# WDTIMER3_DSP register map
Vendor: Texas Instruments
Peripheral module from a debugger description file (folder omap4430).
Registers are 32-bit, access per field, reset 0x0 unless marked. A register's access mark holds for its fields unless they carry their own. Offsets are as the file gives them; lines under a group give offsets from that group; [hi:lo] are bit positions; {n}, {i} and the like mark numbered series; 'fields as' and 'values as' point back to an identical list; <NAME> marks a mode.

## WDTIMER3_DSP
0x00 WDT_WIDR ro reset not defined — IP revision identifier
  [31:0] REVISION — IP Revision
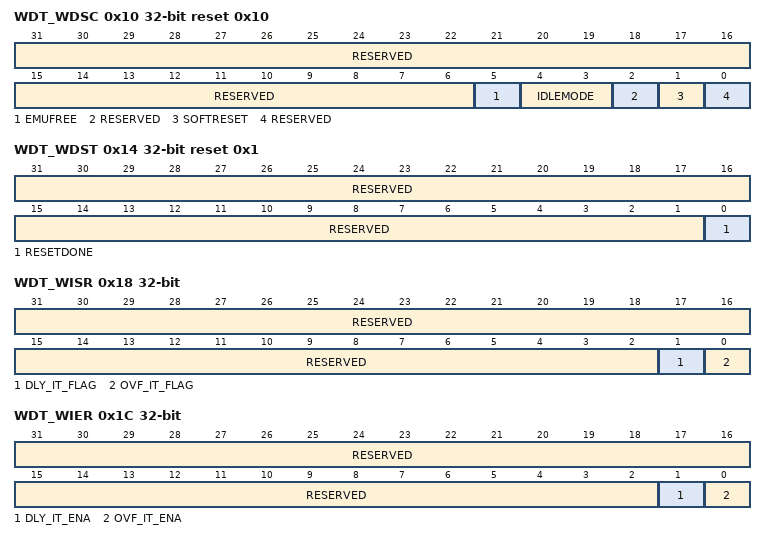
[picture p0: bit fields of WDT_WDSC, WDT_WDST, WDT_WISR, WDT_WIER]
0x10 WDT_WDSC reset 0x10 — This register controls the various parameters of the L4 interface.
  [31:6] RESERVED ro — Write os for future compatibility. Reads return 0.
  [5] EMUFREE rw — Emulation mode
    0=Timer counter frozen in emulation; 1=Timer counter free-running in emulation
  [4:3] IDLEMODE rw — Configuration of the local target state management mode. By definition, target can handle read/write transaction as long as it is out of IDLE state.
    0=Force-idle mode: local target IDLE state follows (acknowledges) the system idle requests unconditionally, that is, regardless of the IP module internal requirements. Backup mode, for debug only.; 1=No-idle mode: local target never enters IDLE state. Backup mode, for debug only.; 2=Smart-idle mode: local target IDLE state eventually follows (acknowledges) the system idle requests, depending on the IP module internal requirements. IP module should not generate (IRQ- or DMA-request-related) wake-up events.; 3=Smart-idle wake-up-capable mode: local target IDLE state eventually follows (acknowledges) the system idle requests, depending on the IP module internal requirements. IP module may generate (IRQ- or DMA-request-related) wake-up events when in IDLE state. Mode is relevant only if the appropriate IP moduleswake-up output(s) is (are) implemented.
  [2] RESERVED ro — Write 0s for future compatibility. Reads return 0.
  [1] SOFTRESET rw — Software reset. (Optional)
    0=SOFTRESET_0_r (Reset done, no pending action); 0=SOFTRESET_0_w (No action); 1=SOFTRESET_1_w (Initiate software reset.); 1=SOFTRESET_1_r (Reset (software or other) ongoing)
  [0] RESERVED ro — Write os for future compatibility. Reads return 0.
0x14 WDT_WDST ro reset 0x1 — This register provides status information about the module.
  [31:1] RESERVED — Reads return 0.
  [0] RESETDONE — Internal module reset monitoring
    0=RESETDONE_0_r (Internal module reset is ongoing.); 1=RESETDONE_1_r (Reset completed)
0x18 WDT_WISR access not given — This register shows which interrupt events are pending inside the module.
  [31:2] RESERVED ro — Reads return 0.
  [1] DLY_IT_FLAG — Pending delay interrupt status. (access RW W1toClr)
    0=DLY_IT_FLAG_0_r (No delay interrupt pending); 0=DLY_IT_FLAG_0_w (Status unchanged); 1=DLY_IT_FLAG_1_w (Status bit cleared); 1=DLY_IT_FLAG_1_r (Delay interrupt pending)
  [0] OVF_IT_FLAG — Pending overflow interrupt status. (access RW W1toClr)
    0=OVF_IT_FLAG_0_r (No overflow interrupt pending); 0=OVF_IT_FLAG_0_w (Status unchanged); 1=OVF_IT_FLAG_1_w (Status bit cleared); 1=OVF_IT_FLAG_1_r (Overflow interrupt pending)
0x1C WDT_WIER — This register controls (enable/disable) the interrupt events.
  [31:2] RESERVED ro — Reads return 0.
  [1] DLY_IT_ENA rw — Delay interrupt enable/disable
    0=Disable delay interrupt; 1=Enable delay interrupt
  [0] OVF_IT_ENA rw — Overflow interrupt enable/disable
    0=Disable overflow interrupt; 1=Enable overflow interrupt
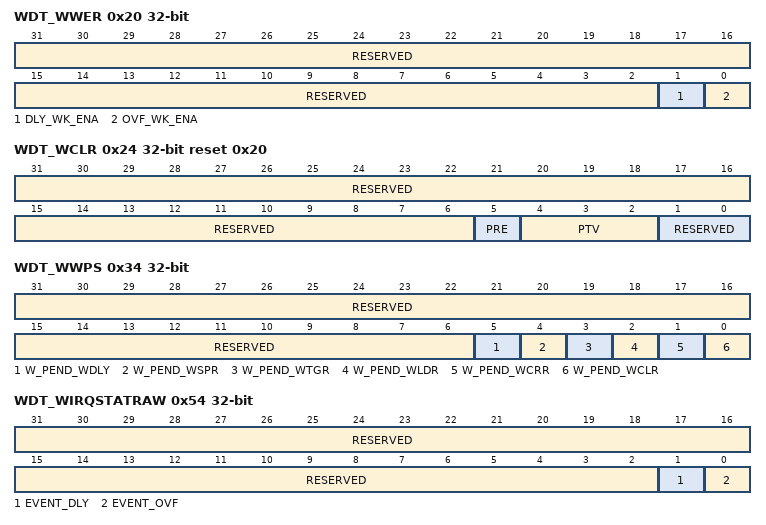
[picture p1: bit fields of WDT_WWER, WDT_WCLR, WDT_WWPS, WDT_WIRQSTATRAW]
0x20 WDT_WWER — This register controls (enable/disable) the wake-up events.
  [31:2] RESERVED ro — Write 0s for future compatibility. Reads return 0.
  [1] DLY_WK_ENA rw — Delay wake-up enable
    0=Disable delay wakeup; 1=Enable delay wakeup
  [0] OVF_WK_ENA rw — Overflow wake-up enable
    0=Disable overflow wakeup; 1=Enable overflow wakeup
0x24 WDT_WCLR reset 0x20 — This register controls the prescaler stage of the counter.
  [31:6] RESERVED ro — Reads return 0.
  [5] PRE rw — Prescaler enable/disable configuration
    0=Prescaler disabled; 1=Prescaler enabled
  [4:2] PTV rw — Prescaler value The timer counter is prescaled with the value: 2. Example: PTV = 3 -&gt; counter increases value if started after 8 functional clock periods. On reset, it is loaded from PI_PTV_RESET_VALUE input port.
  [1:0] RESERVED ro — Write 0s for future compatibility. Reads return 0.
0x28 WDT_WCRR rw — This register holds the value of the internal counter.
  [31:0] TIMER_COUNTER — Value of the timer counter register
0x2C WDT_WLDR rw — This register holds the timer load value.
  [31:0] TIMER_LOAD — Value of the timer load register
0x30 WDT_WTGR rw — Writing a different value than the one already written in this register does a watchdog counter reload.
  [31:0] TTGR_VALUE — Value of the trigger register
0x34 WDT_WWPS ro — This register contains the write posting bits for all writeable functional registers.
  [31:6] RESERVED — Write 0s for future compatibility. Reads return 0.
  [5] W_PEND_WDLY — Write pending for register WDLY
    0=W_PEND_WDLY_0_r (No register write pending); 1=W_PEND_WDLY_1_r (Register write pending)
  [4] W_PEND_WSPR — Write pending for register WSPR
    0=W_PEND_WSPR_0_r (No register write pending); 1=W_PEND_WSPR_1_r (Register write pending)
  [3] W_PEND_WTGR — Write pending for register WTGR
    0=W_PEND_WTGR_0_r (No register write pending); 1=W_PEND_WTGR_1_r (Register write pending)
  [2] W_PEND_WLDR — Write pending for register WLDR
    0=W_PEND_WLDR_0_r (No register write pending); 1=W_PEND_WLDR_1_r (Register write pending)
  [1] W_PEND_WCRR — Write pending for register WCRR
    0=W_PEND_WCRR_0_r (No register write pending); 1=W_PEND_WCRR_1_r (Register write pending)
  [0] W_PEND_WCLR — Write pending for register WCLR
    0=W_PEND_WCLR_0_r (No register write pending); 1=W_PEND_WCLR_1_r (Register write pending)
0x44 WDT_WDLY rw — This register holds the delay value that controls the internal pre-overflow event detection.
  [31:0] WDLY_VALUE — Value of the delay register
0x48 WDT_WSPR rw — This register holds the start-stop value that controls the internal start-stop FSM.
  [31:0] WSPR_VALUE — Value of the start-stop register
0x54 WDT_WIRQSTATRAW access not given — IRQ unmasked status, status set per-event raw interrupt status vector, line 0. Raw status is set even if event is not enabled. Write 1 to set the (raw) status, mostly for debug.
  [31:2] RESERVED ro — Write 0s for future compatibility. Reads return 0.
  [1] EVENT_DLY — Settable raw status for delay event (access RW W1toSet)
    0=EVENT_DLY_0_r (No event pending); 0=EVENT_DLY_0_w (No action); 1=EVENT_DLY_1_w (Set event (debug)); 1=EVENT_DLY_1_r (Event pending)
  [0] EVENT_OVF — Settable raw status for overflow event (access RW W1toSet)
    0=EVENT_OVF_0_r (No event pending); 0=EVENT_OVF_0_w (No action); 1=EVENT_OVF_1_w (Set event (debug)); 1=EVENT_OVF_1_r (Event pending)
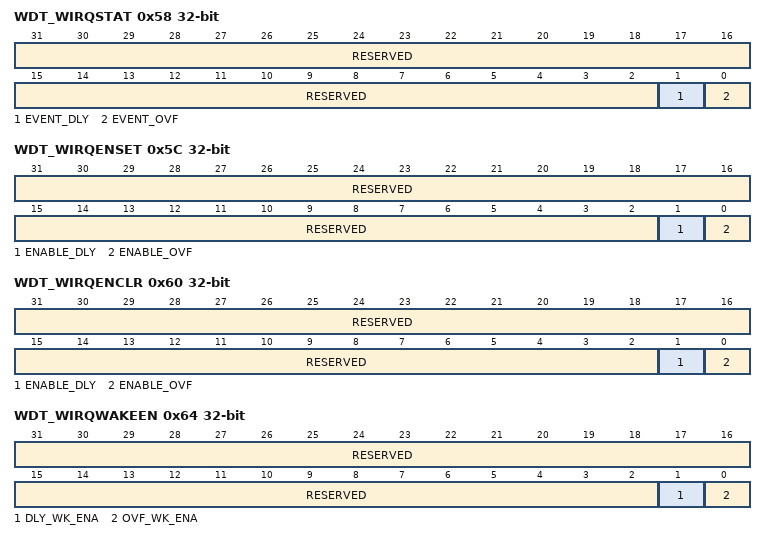
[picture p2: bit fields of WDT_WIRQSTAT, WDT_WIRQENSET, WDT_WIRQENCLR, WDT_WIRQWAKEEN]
0x58 WDT_WIRQSTAT access not given — IRQ masked status, status clear per-event enabled interrupt status vector, line 0. Enabled status is not set unless event is enabled. Write 1 to clear the status after interrupt has been serviced (raw status gets cleared, that is, even if not enabled).
  [31:2] RESERVED ro — Write 0s for future compatibility. Reads return 0.
  [1] EVENT_DLY — Clearable, enabled status for delay event (access RW W1toClr)
    0=EVENT_DLY_0_r (No (enabled) event pending); 0=EVENT_DLY_0_w (No action); 1=EVENT_DLY_1_w (Clear (raw) event); 1=EVENT_DLY_1_r (Event pending)
  [0] EVENT_OVF — Clearable, enabled status for overflow event (access RW W1toClr)
    0=EVENT_OVF_0_r (No (enabled) event pending); 0=EVENT_OVF_0_w (No action); 1=EVENT_OVF_1_w (Clear (raw) event); 1=EVENT_OVF_1_r (Event pending)
0x5C WDT_WIRQENSET access not given — IRQ enable set per-event interrupt enable bit vector, line 0. Write 1 to set (enable interrupt). Readout equal to corresponding _CLR register.
  [31:2] RESERVED ro — Write 0s for future compatibility. Reads return 0.
  [1] ENABLE_DLY — Enable for delay event (access RW W1toSet)
    0=ENABLE_DLY_0_r (Interrupt disabled (masked)); 0=ENABLE_DLY_0_w (No action); 1=ENABLE_DLY_1_w (Enable interrupt.); 1=ENABLE_DLY_1_r (Interrupt enabled)
  [0] ENABLE_OVF — Enable for overflow event (access RW W1toSet)
    0=ENABLE_OVF_0_r (Interrupt disabled (masked)); 0=ENABLE_OVF_0_w (No action); 1=ENABLE_OVF_1_w (Enable interrupt.); 1=ENABLE_OVF_1_r (Interrupt enabled)
0x60 WDT_WIRQENCLR access not given — IRQ enable clear per-event interrupt enable bit vector, line 0. Write 1 to clear (disable interrupt). Readout equal to corresponding _SET register.
  [31:2] RESERVED ro — Write 0s for future compatibility. Reads return 0.
  [1] ENABLE_DLY — Enable for delay event (access RW W1toClr)
    0=ENABLE_DLY_0_r (Interrupt disabled (masked)); 0=ENABLE_DLY_0_w (No action); 1=ENABLE_DLY_1_w (Disable interrupt.); 1=ENABLE_DLY_1_r (Interrupt enabled)
  [0] ENABLE_OVF — Enable for overflow event (access RW W1toClr)
    0=ENABLE_OVF_0_r (Interrupt disabled (masked)); 0=ENABLE_OVF_0_w (No action); 1=ENABLE_OVF_1_w (Disable interrupt.); 1=ENABLE_OVF_1_r (Interrupt enabled)
0x64 WDT_WIRQWAKEEN — This register controls (enable/disable) the wake-up events.
  [31:2] RESERVED ro — Write 0s for future compatibility. Reads return 0.
  [1] DLY_WK_ENA rw — Enable delay wake-up
    0=Disable delay wakeup; 1=Enable delay wakeup
  [0] OVF_WK_ENA rw — Enable overflow wakeup
    0=Disable overflow wakeup; 1=Enable overflow wakeup
